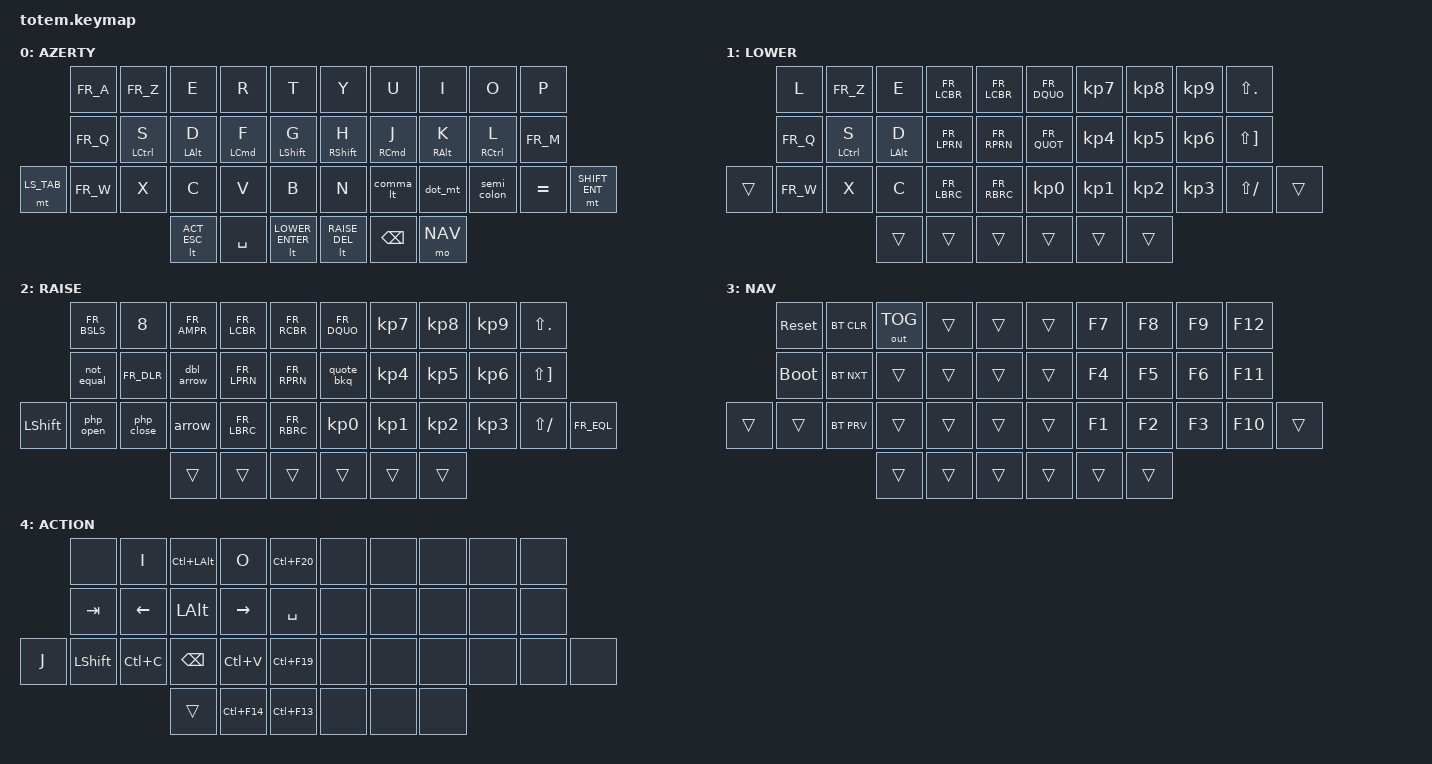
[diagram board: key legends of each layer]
//
//                                                        ▀▀▀▀▀     ▀▀▀▀▀          ▀▀█▀▀
//                                                        ▄▀▀▀▄  ▄  ▄▀▀▀▄  ▄  ▄▀▀▀▄  █  ▄▀▀▀▄
//                                                        █   █  █  █   █  █  █   █  █  █   █
//                                                         ▀▀▀   █   ▀▀▀   █   ▀▀▀   ▀   ▀▀▀
//                                                               █      ▄▄▄█▄▄▄    █   █
//                                                               ▀      █  █  █     █▄█
//                                                             ▀▀▀▀▀    █  █  █      ▀
//                                                                      ▀  ▀  ▀
//
// ▄▄▄▄▄▄▄▄▄▄▄▄▄▄▄▄▄▄▄▄▄▄▄▄▄▄▄▄▄▄▄▄▄▄▄▄▄▄▄▄▄▄▄▄▄▄▄▄▄▄▄▄▄▄▄▄▄▄▄▄▄▄▄▄▄▄▄▄▄▄▄▄▄▄▄▄▄▄▄▄▄▄▄▄▄▄▄▄▄▄▄▄▄▄▄▄▄▄▄▄▄▄▄▄▄▄▄▄▄▄▄▄▄▄▄▄▄▄▄▄▄▄▄▄▄▄▄▄▄▄▄▄▄▄▄▄▄▄▄▄▄▄▄▄▄▄▄▄▄


#include <behaviors.dtsi>
#include <dt-bindings/zmk/keys.h>
#include <dt-bindings/zmk/bt.h>
#include <dt-bindings/zmk/outputs.h>
#include "keymap_french.h"
#include "keypos.h"

#define AZERTY 0
#define LOWER  1
#define RAISE  2
#define NAV    3
#define ACTION 4

#define KEYS_L LT0 LT1 LT2 LT3 LT4 LM0 LM1 LM2 LM3 LM4 LB0 LB1 LB2 LB3 LB4  // left hand
#define KEYS_R RT0 RT1 RT2 RT3 RT4 RM0 RM1 RM2 RM3 RM4 RB0 RB1 RB2 RB3 RB4  // right hand
#define THUMBS LH2 LH1 LH0 RH0 RH1 RH2                                      // thumbs

// Behaviors Constants
#define TAPPING_TERM_MS 280
#define QUICK_TAP_MS 175
#define REQUIRE_PRIOR_IDLE_MS 150

/*
 * Define macros
 */

// LEFT HAND SHIFT / TAB
#define LS_TAB LSHIFT TAB

// RIGHT HAND SHIFT / ENTER
#define SHIFT_ENT RSHIFT ENTER

// Layer keys
#define RAISE_DEL   RAISE DEL    // RAISE, Delete on tap
#define LOWER_ENTER LOWER ENTER  // RAISE, Delete on tap
#define ACT_ESC     ACTION ESC   // ACTION, Escape on tap

// Various French characters
#define M_DOT LS(COMMA)

&mt {
    quick-tap-ms = <100>;
    global-quick-tap;
    flavor = "tap-preferred";
    tapping-term-ms = <170>;
};

/ {

    behaviors {
        /*
         * Home Row Mods
         * - tap: &kp <PARAM_2>
         * - hold: &kp <PARAM_1>
         * Example: &hrml LCMD T
         */
        /omit-if-no-ref/ hrml: hrm_left {
            compatible = "zmk,behavior-hold-tap";
            flavor = "balanced";
            #binding-cells = <2>;
            bindings = <&kp>, <&kp>;
            hold-trigger-key-positions = <KEYS_R THUMBS>;
            hold-trigger-on-release;
            tapping-term-ms = <TAPPING_TERM_MS>;
            quick-tap-ms = <QUICK_TAP_MS>;
            require-prior-idle-ms = <REQUIRE_PRIOR_IDLE_MS>;
        };
        /omit-if-no-ref/ hrmr: hrm_right {
            compatible = "zmk,behavior-hold-tap";
            flavor = "balanced";
            #binding-cells = <2>;
            bindings = <&kp>, <&kp>;
            hold-trigger-key-positions = <KEYS_L THUMBS>;
            hold-trigger-on-release;
            tapping-term-ms = <TAPPING_TERM_MS>;
            quick-tap-ms = <QUICK_TAP_MS>;
            require-prior-idle-ms = <REQUIRE_PRIOR_IDLE_MS>;
        };

        /*
         * - tap: sticky shift
         * - double-tap: caps-word (shift + tap mod-morph)
         * - hold: shift
         * From: https://github.com/urob/zmk-config/
         */
        /omit-if-no-ref/ smart_shift: smart_shift {
            compatible = "zmk,behavior-mod-morph";
            #binding-cells = <0>;
            bindings = <&sk RSHFT>, <&caps_word>;
            mods = <(MOD_RSFT)>;
        };

        comma_lt: comma_lessthan {
            compatible = "zmk,behavior-mod-morph";
            #binding-cells = <0>;
            bindings = <&kp M>, <&kp GRAVE>;
            mods = <(MOD_LSFT|MOD_RSFT)>;
        };

        dot_mt: dot_morethan {
            compatible = "zmk,behavior-mod-morph";
            #binding-cells = <0>;
            bindings = <&kp LS(COMMA)>, <&kp LS(GRAVE)>;
            mods = <(MOD_LSFT|MOD_RSFT)>;
        };

        semi_colon: semicolon_colon {
            compatible = "zmk,behavior-mod-morph";
            #binding-cells = <0>;
            bindings = <&kp COMMA>, <&kp DOT>;
            mods = <(MOD_LSFT|MOD_RSFT)>;
        };

        quote_bkq: quote_bkq {
            compatible = "zmk,behavior-mod-morph";
            #binding-cells = <0>;
            bindings = <&kp N4>, <&kp NUHS>;
            mods = <(MOD_LSFT|MOD_RSFT)>;
        };
    };

    macros {
        not_equal: not_equal {
            compatible = "zmk,behavior-macro";
            #binding-cells = <0>;
            wait-ms = <40>;
            tap-ms = <40>;
            bindings = <&kp N8 &kp SLASH>;
        };

        php_open: php_open {
            compatible = "zmk,behavior-macro";
            #binding-cells = <0>;
            wait-ms = <40>;
            tap-ms = <40>;
            bindings = <&kp GRAVE &kp LS(M)>;
        };

        php_close: php_close {
            compatible = "zmk,behavior-macro";
            #binding-cells = <0>;
            wait-ms = <40>;
            tap-ms = <40>;
            bindings = <&kp LS(M) &kp LS(GRAVE)>;
        };

        arrow: arrow {
            compatible = "zmk,behavior-macro";
            #binding-cells = <0>;
            wait-ms = <40>;
            tap-ms = <40>;
            bindings = <&kp EQUAL &kp LS(GRAVE)>;
        };

        dbl_arrow: dbl_arrow {
            compatible = "zmk,behavior-macro";
            #binding-cells = <0>;
            wait-ms = <40>;
            tap-ms = <40>;
            bindings = <&kp SLASH &kp LS(GRAVE)>;
        };
    };


// K E Y M A P
// =============

    keymap {
        compatible = "zmk,keymap";

/*
 * AZERTY
 * ——————
 *             +-----------+-----------+-----------+-----------+-----------+  +-----------+-----------+-----------+-----------+-----------+
 *             |     A     |     Z     |     E     |     R     |     T     |  |     Y     |     U     |     I     |     O     |     P     |
 *             +-----------+-----------+-----------+-----------+-----------+  +-----------+-----------+-----------+-----------+-----------+
 *             |     Q     |     S     |     D     |     F     |     G     |  |     H     |     J     |     K     |     L     |     M     |
 * +-----------+-----------+-----------+-----------+-----------+-----------+  +-----------+-----------+-----------+-----------+-----------+-----------+
 * |   TAB     |     W     |     X     |     C     |     V     |     B     |  |     N     |     ,     |     .     |     ;     |     -     |   ENTER   |
 * +-----------+-----------+-----------+-----------+-----------+-----------+  +-----------+-----------+-----------+-----------+-----------+-----------+
 *                                     |    ESC    |   SPACE   |   LOWER   |  |   RAISE   |   BKSPC   |    NAV    |
 *                                     +-----------+-----------+-----------+  +-----------+-----------+-----------+
 */

        base_layer {
            label = "AZERTY";
            bindings = <
// +-------------+-------------+-------------+-------------+-------------+-------------+  +-------------+-------------+-------------+-------------+-------------+-------------+
                  &kp FR_A      &kp FR_Z      &kp E         &kp R         &kp T            &kp Y         &kp U         &kp I         &kp O         &kp P
                  &kp FR_Q      &hrml LCTRL S &hrml LALT D  &hrml LCMD F  &hrml LSHFT G    &hrmr RSHFT H &hrml RCMD J  &hrml RALT K  &hrml RCTRL L &kp FR_M
    &mt LS_TAB    &kp FR_W      &kp X         &kp C         &kp V         &kp B            &kp N         &comma_lt     &dot_mt       &semi_colon   &kp EQUAL     &mt SHIFT_ENT
                                              &lt ACT_ESC   &kp SPACE     &lt LOWER_ENTER  &lt RAISE_DEL &kp BSPC      &mo NAV
            >;
        };



        lower_layer {
            label= "LOWER";
            bindings = <
// +-------------+-------------+-------------+-------------+-------------+-------------+  +-------------+-------------+-------------+-------------+-------------+-------------+

                  &kp L         &kp FR_Z      &kp E         &kp FR_LCBR   &kp FR_LCBR      &kp FR_DQUO   &kp KP_N7     &kp KP_N8     &kp KP_N9     &kp LS(DOT)
                  &kp FR_Q      &hrml LCTRL S &hrml LALT D  &kp FR_LPRN   &kp FR_RPRN      &kp FR_QUOT   &kp KP_N4     &kp KP_N5     &kp KP_N6     &kp LS(RBKT)
    &trans        &kp FR_W      &kp X         &kp C         &kp FR_LBRC   &kp FR_RBRC      &kp KP_N0     &kp KP_N1     &kp KP_N2     &kp KP_N3     &kp LS(SLASH) &trans
                                              &trans        &trans        &trans           &trans        &trans        &trans
            >;
        };



        raise_layer {
            label= "RAISE";
            bindings = <
// +-------------+-------------+-------------+-------------+-------------+-------------+  +-------------+-------------+-------------+-------------+-------------+-------------+

                  &kp FR_BSLS   &kp N8        &kp FR_AMPR   &kp FR_LCBR   &kp FR_RCBR      &kp FR_DQUO   &kp KP_N7     &kp KP_N8     &kp KP_N9     &kp LS(DOT)
                  &not_equal    &kp FR_DLR    &dbl_arrow    &kp FR_LPRN   &kp FR_RPRN      &quote_bkq    &kp KP_N4     &kp KP_N5     &kp KP_N6     &kp LS(RBKT)
    &kp LSHFT     &php_open     &php_close    &arrow        &kp FR_LBRC   &kp FR_RBRC      &kp KP_N0     &kp KP_N1     &kp KP_N2     &kp KP_N3     &kp LS(SLASH) &kp FR_EQL
                                              &trans        &trans        &trans           &trans        &trans        &trans
            >;
        };



        nav_layer {
            label= "NAV";
            bindings = <
// +-------------+-------------+-------------+-------------+-------------+-------------+  +-------------+-------------+-------------+-------------+-------------+-------------+

                &sys_reset  &bt BT_CLR &out OUT_TOG &trans      &trans          &trans      &kp F7      &kp F8      &kp F9      &kp F12
                &bootloader &bt BT_NXT  &trans      &trans      &trans          &trans      &kp F4      &kp F5      &kp F6      &kp F11
    &trans      &trans      &bt BT_PRV  &trans      &trans      &trans          &trans      &kp F1      &kp F2      &kp F3      &kp F10     &trans
                                        &trans      &trans      &trans          &trans      &trans      &trans
            >;
        };



        action_layer {
            label= "ACTION";
            bindings = <
// +-------------+-------------+-------------+-------------+-------------+-------------+  +-------------+-------------+-------------+-------------+-------------+-------------+

                &none       &kp I       &kp LC(LALT) &kp O      &kp LC(F20)     &none       &none       &none       &none       &none
                &kp TAB     &kp LEFT    &kp LALT    &kp RIGHT   &kp SPACE       &none       &none       &none       &none       &none
    &kp J       &kp LSHFT   &kp LC(C)   &kp BSPC    &kp LC(V)   &kp LC(F19)     &none       &none       &none       &none       &none       &none
                                        &trans      &kp LC(F14) &kp LC(F13)     &none       &none       &none
            >;
        };
    };
};
